# ESP32S31_RADIO register map
Vendor: Espressif; Series: ESP32-S31; File version: 3.52
Registers are 32-bit, read-write, no defined reset value unless marked. A register's access mark holds for its fields unless they carry their own. Offsets are from the block's base; [hi:lo] are bit positions; {n}, {i} and the like mark numbered series; 'fields as' and 'values as' point back to an identical list.

## BLUETOOTH_INTERRUPT_BANK — Bluetooth controller interrupt programming, enable, status, acknowledgement, snapshot and diagnostic registers. This physical view is independent from the controller task lifecycle so ownership can transfer to the hard ISR without also exposing scheduler, sleep or memory-management state.
Base 0x20101000
0x0C IRQ_CONTROL_0 wo — Project-assigned name. BTDM interrupt setup and the complete reset leaf write the finite complete image 1. Inner action remains unknown.
  [31:0] COMMAND — Project-assigned name.
0x10 IRQ_CONTROL_1 wo — Project-assigned name. BTDM interrupt teardown and the complete reset leaf write the finite complete image 1. Inner action remains unknown.
  [31:0] COMMAND — Project-assigned name.
0x14 IRQ_CONTROL_2 wo — Project-assigned name. BTDM interrupt teardown and the complete reset leaf write the finite complete image 1. Inner action remains unknown.
  [31:0] COMMAND — Project-assigned name.
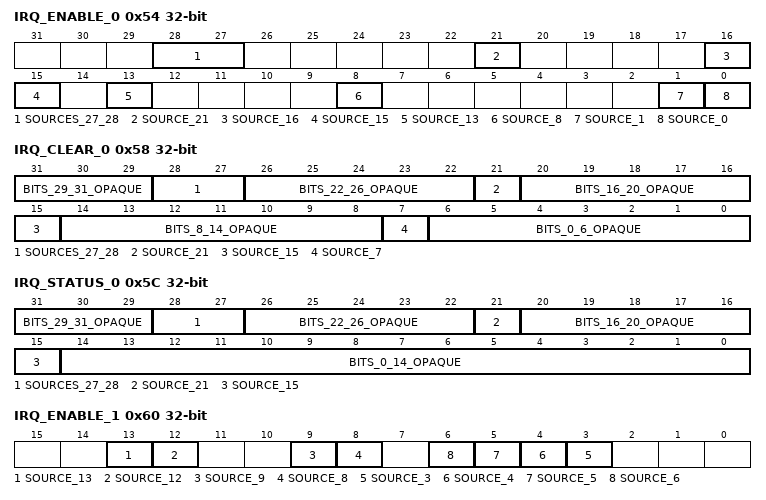
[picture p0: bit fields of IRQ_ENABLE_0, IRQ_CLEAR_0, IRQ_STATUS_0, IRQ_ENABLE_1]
0x54 IRQ_ENABLE_0 — Project-assigned name. First controller interrupt-enable bank. Primary setup clears stale image 0x00008000 then ORs that baseline into this word; another complete helper independently controls 0x18200000.
  [28:27] SOURCES_27_28 — Project-assigned name.
  [21] SOURCE_21 — Project-assigned name.
  [16] SOURCE_16 — Project-assigned name.
  [15] SOURCE_15 — Project-assigned name.
  [13] SOURCE_13 — Project-assigned name.
  [8] SOURCE_8 — Project-assigned name.
  [1] SOURCE_1 — Project-assigned name.
  [0] SOURCE_0 — Project-assigned name.
0x58 IRQ_CLEAR_0 wo write-1-clears — Project-assigned name. First controller interrupt-clear bank. Primary and NRT handlers copy their respective first-bank status images here as complete words.
  [31:29] BITS_29_31_OPAQUE — Opaque: meaning not established.
  [28:27] SOURCES_27_28 — Project-assigned name.
  [26:22] BITS_22_26_OPAQUE — Opaque: meaning not established.
  [21] SOURCE_21 — Project-assigned name.
  [20:16] BITS_16_20_OPAQUE — Opaque: meaning not established.
  [15] SOURCE_15 — Project-assigned name.
  [14:8] BITS_8_14_OPAQUE — Opaque: meaning not established.
  [7] SOURCE_7 — Project-assigned name. Acknowledged with complete image 0x80 by the scheduler cancellation path before it sets BLUETOOTH_CONTROLLER_CORE.WORD_0204_OPAQUE bit zero.
  [6:0] BITS_0_6_OPAQUE — Opaque: meaning not established.
0x5C IRQ_STATUS_0 ro — Project-assigned name. First masked controller interrupt-status bank; the primary source-124 handler reads this complete word before acknowledgement.
  [31:29] BITS_29_31_OPAQUE — Opaque: meaning not established.
  [28:27] SOURCES_27_28 — Project-assigned name.
  [26:22] BITS_22_26_OPAQUE — Opaque: meaning not established.
  [21] SOURCE_21 — Project-assigned name.
  [20:16] BITS_16_20_OPAQUE — Opaque: meaning not established.
  [15] SOURCE_15 — Project-assigned name.
  [14:0] BITS_0_14_OPAQUE — Opaque: meaning not established.
0x60 IRQ_ENABLE_1 — Project-assigned name. Second controller interrupt-enable bank. Primary setup clears stale image 0x00001300 then ORs that baseline into this word; another complete helper independently controls bit 3.
  [13] SOURCE_13 — Project-assigned name.
  [12] SOURCE_12 — Project-assigned name.
  [9] SOURCE_9 — Project-assigned name.
  [8] SOURCE_8 — Project-assigned name.
  [n] SOURCE_{n} (n=3..6) — Project-assigned name.
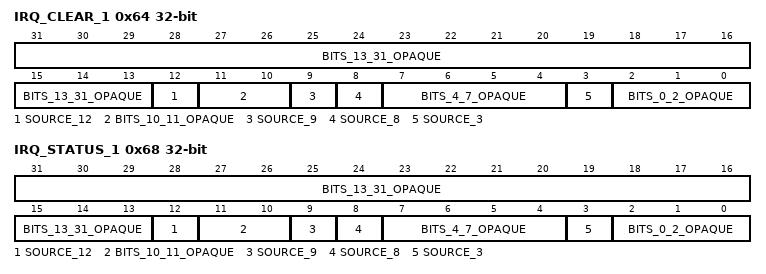
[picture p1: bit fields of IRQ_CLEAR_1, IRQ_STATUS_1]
0x64 IRQ_CLEAR_1 wo write-1-clears — Project-assigned name. Second controller interrupt-clear bank. Primary and NRT handlers copy their respective second-bank status images here as complete words.
  [31:13] BITS_13_31_OPAQUE — Opaque: meaning not established.
  [12] SOURCE_12 — Project-assigned name.
  [11:10] BITS_10_11_OPAQUE — Opaque: meaning not established.
  [9] SOURCE_9 — Project-assigned name.
  [8] SOURCE_8 — Project-assigned name.
  [7:4] BITS_4_7_OPAQUE — Opaque: meaning not established.
  [3] SOURCE_3 — Project-assigned name.
  [2:0] BITS_0_2_OPAQUE — Opaque: meaning not established.
0x68 IRQ_STATUS_1 ro — Project-assigned name. Second masked controller interrupt-status bank; the primary source-124 handler reads this complete word before acknowledgement.
  fields as IRQ_CLEAR_1
0x70 IRQ_DIAGNOSTIC_STATE ro — Project-assigned name. Complete word read by the primary source-124 fault prefix when masked bank-one source 12 is pending. Inner state encoding remains unknown.
  [31:0] VALUE — Project-assigned name.
0x1C8 IRQ_DIAGNOSTIC_DETAIL_0 ro — Project-assigned name. First complete detail word read by the primary source-124 fault prefix when masked bank-one source 9 is pending. Inner encoding remains unknown.
  [31:0] VALUE — Project-assigned name.
0x1CC IRQ_DIAGNOSTIC_DETAIL_1 ro — Project-assigned name. Second complete detail word read by the primary source-124 fault prefix when masked bank-one source 9 is pending. Inner encoding remains unknown.
  [31:0] VALUE — Project-assigned name.
0x340 IRQ_STATUS_SNAPSHOT_0 ro — Project-assigned name. Raw first-bank status snapshot read by the NRT ISR and copied to IRQ_CLEAR_0.
  [31:0] PENDING_BITS — Project-assigned name.
0x348 IRQ_STATUS_SNAPSHOT_1 ro — Project-assigned name. Raw second-bank status snapshot read by the NRT ISR and copied to IRQ_CLEAR_1.
  [31:0] PENDING_BITS — Project-assigned name.
